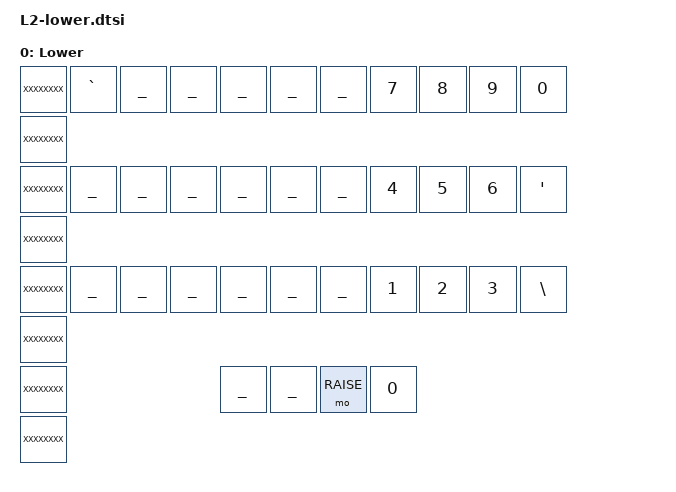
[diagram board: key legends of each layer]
/**
 *
 */

/ {
  keymap {
    compatible = "zmk,keymap";

	lower_layer {
		label = "Lower";
		bindings = <
// ├───────────────├───────────────┼───────────────┼───────────────┼───────────────┼───────────────┤   ├───────────────├───────────────┼───────────────┼───────────────┼───────────────┼───────────────┤
//  12              13              14              15              16              17                  18              19              20              21              22              23
	XXXXXXXX        &lang_ex    	&kp INS       	&kp HOME        &kp PG_UP       MOVE_LEFT        	MOVE_RIGHT      &kp MINUS     	&kp KP_PLUS		&kp LBKT       	&kp RBKT        XXXXXXXX
// ├───────────────├───────────────┼───────────────┼───────────────┼───────────────┼───────────────┤   ├───────────────├───────────────┼───────────────┼───────────────┼───────────────┼───────────────┤
//  24              25              26              27              28              29                  30              31              32              33              34              35
    XXXXXXXX      	&tog COLEMAK    &kp DEL        	&kp END        	&kp PG_DN       &macro_nerd_l		&macro_nerd_r   &kp UNDER  		&kp EQUAL       XXXXXXXX        &kp BSLH        XXXXXXXX
// ╰───────────────┴───────────────┴───────────────┼───────────────┼───────────────┼───────────────┤   ├───────────────├───────────────┼───────────────┼───────────────┴───────────────┴───────────────╯
//                                                  36              37              38                  39              40              41
                                    	            XXXXXXXX       	________        ________           	&mo RAISE		________		XXXXXXXX
//                                                 ╰───────────────┴───────────────┴───────────────╯   ╰───────────────┴───────────────┴───────────────
			>;

   		bindings = <
//					╭───────────────┬───────────────┬───────────────┬───────────────┬───────────────╮   ╭───────────────┬───────────────┬───────────────┬───────────────┬───────────────╮
//  0               	1               2               3               4               5                   6               7               8               9               10
	XXXXXXXX			&kp GRAVE		________    	________		________		________			________        &kp N7			&kp N8       	&kp N9        	&kp N0
	XXXXXXXX	//	├───────────────┼───────────────┼───────────────┼───────────────┼───────────────┤   ├───────────────├───────────────┼───────────────┼───────────────┼───────────────┤
//  12					13              14              15              16              17                  18              19              20              21              22
	XXXXXXXX			________		________    	________		________		________			________		&kp N4			&kp N5       	&kp N6			&kp SQT
	XXXXXXXX	//	├───────────────┼───────────────┼───────────────┼───────────────┼───────────────┤   ├───────────────├───────────────┼───────────────┼───────────────┼───────────────┤
//  24					25              26              27              28              29                  30              31              32              33              34
	XXXXXXXX			________		________    	________		________		________			________		&kp N1			&kp N2       	&kp N3			&kp BSLH
	XXXXXXXX	//	╰───────────────┴───────────────┼───────────────┼───────────────┼───────────────┤   ├───────────────├───────────────┼───────────────┼───────────────┴───────────────╯
//	36              													37              38                  39              40
	XXXXXXXX       														________		________			&mo RAISE		&kp N0
//                                                                  ╰───────────────┴───────────────╯   ╰───────────────┴───────────────╯ tab enter space bspc raise lower
	XXXXXXXX
			>;


		};
	};
};
